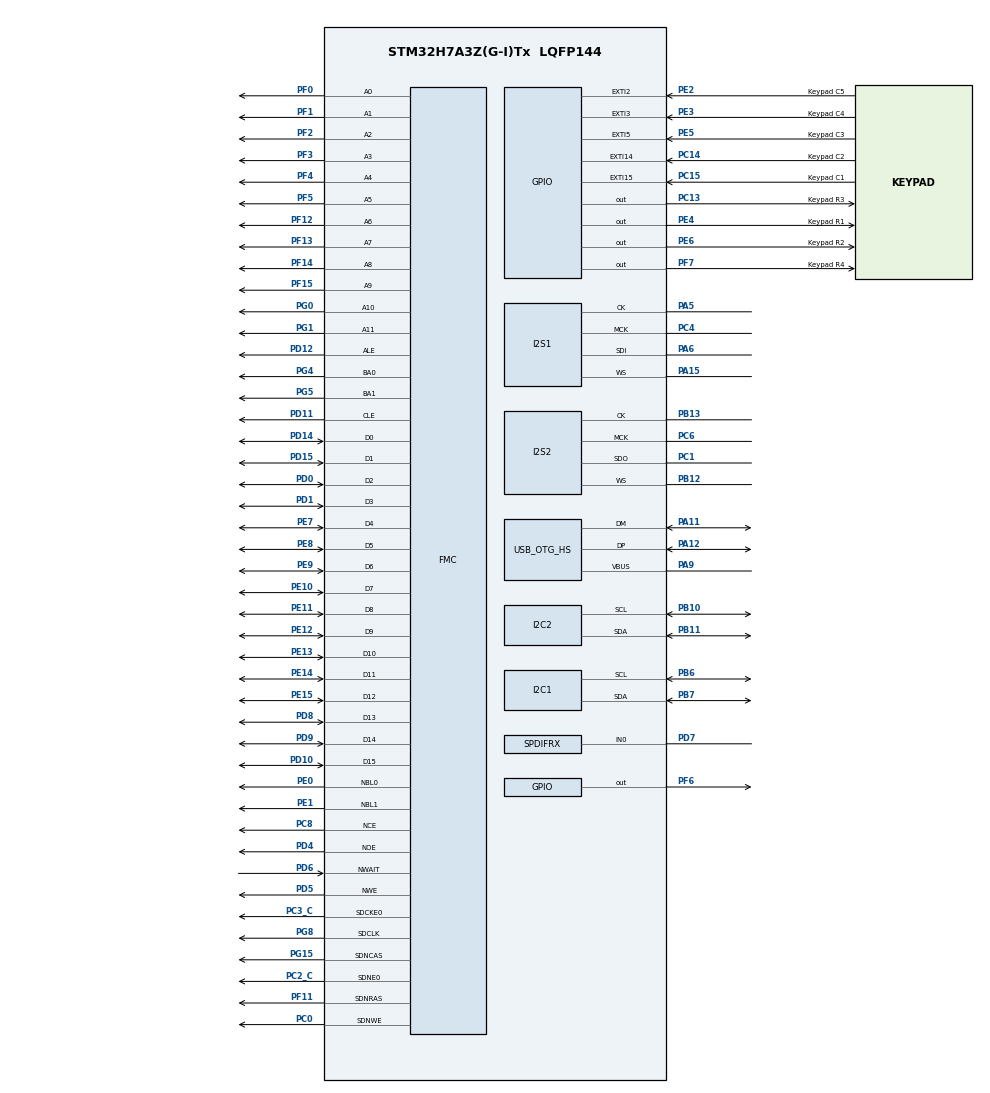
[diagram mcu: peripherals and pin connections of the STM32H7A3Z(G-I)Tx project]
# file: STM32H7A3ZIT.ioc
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CORTEX_M7.AccessPermission_S-Cortex_Memory_Protection_Unit_Region1_Settings_S=MPU_REGION_FULL_ACCESS
CORTEX_M7.AccessPermission_S-Cortex_Memory_Protection_Unit_Region2_Settings_S=MPU_REGION_FULL_ACCESS
CORTEX_M7.BaseAddress_S-Cortex_Memory_Protection_Unit_Region1_Settings_S=0xC0000000
CORTEX_M7.BaseAddress_S-Cortex_Memory_Protection_Unit_Region2_Settings_S=0x80000000
CORTEX_M7.DisableExec_S-Cortex_Memory_Protection_Unit_Region2_Settings_S=MPU_INSTRUCTION_ACCESS_ENABLE
CORTEX_M7.Enable_S-Cortex_Memory_Protection_Unit_Region1_Settings_S=MPU_REGION_ENABLE
CORTEX_M7.Enable_S-Cortex_Memory_Protection_Unit_Region2_Settings_S=MPU_REGION_ENABLE
CORTEX_M7.IsBufferable_S-Cortex_Memory_Protection_Unit_Region1_Settings_S=MPU_ACCESS_NOT_BUFFERABLE
CORTEX_M7.IsBufferable_S-Cortex_Memory_Protection_Unit_Region2_Settings_S=MPU_ACCESS_NOT_BUFFERABLE
CORTEX_M7.IsShareable_S-Cortex_Memory_Protection_Unit_Region1_Settings_S=MPU_ACCESS_SHAREABLE
CORTEX_M7.IsShareable_S-Cortex_Memory_Protection_Unit_Region2_Settings_S=MPU_ACCESS_SHAREABLE
CORTEX_M7.Size_S-Cortex_Memory_Protection_Unit_Region1_Settings_S=MPU_REGION_SIZE_16MB
CORTEX_M7.Size_S-Cortex_Memory_Protection_Unit_Region2_Settings_S=MPU_REGION_SIZE_256MB
CORTEX_M7.TypeExtField_S-Cortex_Memory_Protection_Unit_Region1_Settings_S=MPU_TEX_LEVEL1
CORTEX_M7.TypeExtField_S-Cortex_Memory_Protection_Unit_Region2_Settings_S=MPU_TEX_LEVEL1
CORTEX_M7.default_mode_Activation=1
Dma.Request0=SPI1_RX
Dma.Request1=SPI2_TX
Dma.SPI1_RX.0.Direction=DMA_PERIPH_TO_MEMORY
Dma.SPI1_RX.0.EventEnable=DISABLE
Dma.SPI1_RX.0.FIFOMode=DMA_FIFOMODE_DISABLE
Dma.SPI1_RX.0.Instance=DMA1_Stream0
Dma.SPI1_RX.0.MemDataAlignment=DMA_MDATAALIGN_HALFWORD
Dma.SPI1_RX.0.MemInc=DMA_MINC_ENABLE
Dma.SPI1_RX.0.Mode=DMA_CIRCULAR
Dma.SPI1_RX.0.PeriphDataAlignment=DMA_PDATAALIGN_HALFWORD
Dma.SPI1_RX.0.PeriphInc=DMA_PINC_DISABLE
Dma.SPI1_RX.0.Polarity=HAL_DMAMUX_REQ_GEN_RISING
Dma.SPI1_RX.0.Priority=DMA_PRIORITY_LOW
Dma.SPI1_RX.0.RequestNumber=1
Dma.SPI1_RX.0.SignalID=NONE
Dma.SPI1_RX.0.SyncEnable=DISABLE
Dma.SPI1_RX.0.SyncPolarity=HAL_DMAMUX_SYNC_NO_EVENT
Dma.SPI1_RX.0.SyncRequestNumber=1
Dma.SPI1_RX.0.SyncSignalID=NONE
Dma.SPI2_TX.1.Direction=DMA_MEMORY_TO_PERIPH
Dma.SPI2_TX.1.EventEnable=DISABLE
Dma.SPI2_TX.1.FIFOMode=DMA_FIFOMODE_DISABLE
Dma.SPI2_TX.1.Instance=DMA1_Stream1
Dma.SPI2_TX.1.MemDataAlignment=DMA_MDATAALIGN_HALFWORD
Dma.SPI2_TX.1.MemInc=DMA_MINC_ENABLE
Dma.SPI2_TX.1.Mode=DMA_CIRCULAR
Dma.SPI2_TX.1.PeriphDataAlignment=DMA_PDATAALIGN_HALFWORD
Dma.SPI2_TX.1.PeriphInc=DMA_PINC_DISABLE
Dma.SPI2_TX.1.Polarity=HAL_DMAMUX_REQ_GEN_RISING
Dma.SPI2_TX.1.Priority=DMA_PRIORITY_LOW
Dma.SPI2_TX.1.RequestNumber=1
Dma.SPI2_TX.1.SignalID=NONE
Dma.SPI2_TX.1.SyncEnable=DISABLE
Dma.SPI2_TX.1.SyncPolarity=HAL_DMAMUX_SYNC_NO_EVENT
Dma.SPI2_TX.1.SyncRequestNumber=1
Dma.SPI2_TX.1.SyncSignalID=NONE
FMC.AttributeSpaceHiZSetupTime1=2
FMC.AttributeSpaceHoldSetupTime1=1
FMC.AttributeSpaceSetupTime1=0
FMC.AttributeSpaceWaitSetupTime1=1
FMC.CASLatency1=FMC_SDRAM_CAS_LATENCY_3
FMC.ColumnBitsNumber1=FMC_SDRAM_COLUMN_BITS_NUM_9
FMC.CommonSpaceHiZSetupTime1=5
FMC.CommonSpaceHoldSetupTime1=2
FMC.CommonSpaceSetupTime1=1
FMC.CommonSpaceWaitSetupTime1=2
FMC.EccComputation1=FMC_NAND_ECC_ENABLE
FMC.ExitSelfRefreshDelay1=9
FMC.LoadToActiveDelay1=2
FMC.NandBlockNbr1=2048
FMC.NandBlockSize1=64
FMC.NandExtraCommandEnable1=ENABLE
FMC.NandPageSize1=2112
FMC.NandPlaneNbr1=1
FMC.NandSpareAreaSize1=64
FMC.RCDDelay1=3
FMC.RPDelay1=3
FMC.RPDelay2=3
FMC.ReadBurst1=FMC_SDRAM_RBURST_DISABLE
FMC.RowCycleDelay1=9
FMC.RowCycleDelay2=9
FMC.SDClockPeriod1=FMC_SDRAM_CLOCK_PERIOD_2
FMC.SDClockPeriod2=FMC_SDRAM_CLOCK_PERIOD_2
FMC.SelfRefreshTime1=6
FMC.WriteProtection1=FMC_SDRAM_WRITE_PROTECTION_DISABLE
FMC.WriteRecoveryTime1=3
I2C1.Timing=0x20B0CCFF
I2C2.Timing=0x20B0CCFF
I2S1.AudioFreq=I2S_AUDIOFREQ_8K
I2S1.CPOL=I2S_CPOL_LOW
I2S1.DataFormat=I2S_DATAFORMAT_16B
I2S1.ErrorAudioFreq=0.07 %
I2S1.Instance=SPI$Index
I2S1.MasterKeepIOState=I2S_MASTER_KEEP_IO_STATE_ENABLE
I2S1.RealAudioFreq=8.006 KHz
I2S1.Standard=I2S_STANDARD_PHILIPS
I2S2.AudioFreq=I2S_AUDIOFREQ_8K
I2S2.DataFormat=I2S_DATAFORMAT_16B
I2S2.ErrorAudioFreq=0.07 %
I2S2.FirstBit=I2S_FIRSTBIT_MSB
I2S2.Instance=SPI$Index
I2S2.MasterKeepIOState=I2S_MASTER_KEEP_IO_STATE_ENABLE
I2S2.RealAudioFreq=8.006 KHz
Mcu.Family=STM32H7
Mcu.Name=STM32H7A3Z(G-I)Tx
Mcu.Package=LQFP144
NVIC.DMA1_Stream0_IRQn=true\:4\:0\:true\:false\:true\:false\:true\:true
NVIC.DMA1_Stream1_IRQn=true\:4\:0\:true\:false\:true\:true\:true\:true
NVIC.EXTI15_10_IRQn=true\:3\:0\:true\:true\:true\:4\:true\:true\:true
NVIC.EXTI2_IRQn=true\:3\:0\:true\:true\:true\:1\:true\:true\:true
NVIC.EXTI3_IRQn=true\:3\:0\:true\:true\:true\:2\:true\:true\:true
NVIC.EXTI9_5_IRQn=true\:3\:0\:true\:true\:true\:3\:true\:true\:true
NVIC.OTG_HS_EP1_IN_IRQn=true\:0\:0\:false\:false\:true\:true\:true\:true
NVIC.OTG_HS_EP1_OUT_IRQn=true\:0\:0\:false\:false\:true\:true\:true\:true
NVIC.OTG_HS_IRQn=true\:0\:0\:false\:false\:true\:false\:true\:true
NVIC.PriorityGroup=NVIC_PRIORITYGROUP_4
NVIC.SPDIF_RX_IRQn=true\:0\:0\:false\:false\:true\:true\:true\:true
NVIC.SPI1_IRQn=true\:0\:0\:false\:false\:true\:true\:true\:true
NVIC.SPI2_IRQn=true\:0\:0\:false\:false\:true\:true\:true\:true
NVIC.TIM2_IRQn=true\:0\:0\:false\:false\:true\:true\:true\:true
PA11.GPIO_PuPd=GPIO_NOPULL
PA11.Mode=Device_Only_FS
PA11.Signal=USB_OTG_HS_DM
PA12.GPIO_PuPd=GPIO_PULLUP
PA12.Mode=Device_Only_FS
PA12.Signal=USB_OTG_HS_DP
PA13.Mode=Serial_Wire
PA13.Signal=DEBUG_JTMS-SWDIO
PA14.Mode=Serial_Wire
PA14.Signal=DEBUG_JTCK-SWCLK
PA15.Mode=Half_Duplex_Master_Rx
PA15.Signal=I2S1_WS
PA5.Mode=Half_Duplex_Master_Rx
PA5.Signal=I2S1_CK
PA6.Mode=Half_Duplex_Master_Rx
PA6.Signal=I2S1_SDI
PA9.Mode=Activate_VBUS_FS
PA9.Signal=USB_OTG_HS_VBUS
PB10.Mode=I2C
PB10.Signal=I2C2_SCL
PB11.Mode=I2C
PB11.Signal=I2C2_SDA
PB12.Mode=Half_Duplex_Master_Tx
PB12.Signal=I2S2_WS
PB13.Mode=Half_Duplex_Master_Tx
PB13.Signal=I2S2_CK
PB6.Mode=I2C
PB6.Signal=I2C1_SCL
PB7.Mode=I2C
PB7.Signal=I2C1_SDA
PC0.Signal=FMC_SDNWE
PC1.Mode=Half_Duplex_Master_Tx
PC1.Signal=I2S2_SDO
PC13.GPIO_Label=Keypad R3
PC13.GPIO_ModeDefaultOutputPP=GPIO_MODE_OUTPUT_PP
PC13.GPIO_PuPd=GPIO_NOPULL
PC13.Signal=GPIO_Output
PC14-OSC32_IN.GPIO_Label=Keypad C2
PC14-OSC32_IN.GPIO_ModeDefaultEXTI=GPIO_MODE_IT_FALLING
PC14-OSC32_IN.GPIO_PuPd=GPIO_PULLUP
PC14-OSC32_IN.Signal=GPXTI14
PC15-OSC32_OUT.GPIO_Label=Keypad C1
PC15-OSC32_OUT.GPIO_ModeDefaultEXTI=GPIO_MODE_IT_FALLING
PC15-OSC32_OUT.GPIO_PuPd=GPIO_PULLUP
PC15-OSC32_OUT.Signal=GPXTI15
PC2_C.Mode=SdramChipSelect1_1
PC2_C.Signal=FMC_SDNE0
PC3_C.Mode=SdramChipSelect1_1
PC3_C.Signal=FMC_SDCKE0
PC4.Mode=Master_Clock_Activated
PC4.Signal=I2S1_MCK
PC6.Mode=Master_Clock_Activated
PC6.Signal=I2S2_MCK
PC8.Mode=NandChipSelect3_1
PC8.Signal=FMC_NCE
PD0.Signal=FMC_D2_DA2
PD1.Signal=FMC_D3_DA3
PD10.Signal=FMC_D15_DA15
PD11.Signal=FMC_A16_CLE
PD12.Signal=FMC_A17_ALE
PD14.Signal=FMC_D0_DA0
PD15.Signal=FMC_D1_DA1
PD4.Signal=FMC_NOE
PD5.Signal=FMC_NWE
PD6.Signal=FMC_NWAIT
PD7.Mode=IN0
PD7.Signal=SPDIFRX_IN0
PD8.Signal=FMC_D13_DA13
PD9.Signal=FMC_D14_DA14
PE0.Signal=FMC_NBL0
PE1.Signal=FMC_NBL1
PE10.Signal=FMC_D7_DA7
PE11.Signal=FMC_D8_DA8
PE12.Signal=FMC_D9_DA9
PE13.Signal=FMC_D10_DA10
PE14.Signal=FMC_D11_DA11
PE15.Signal=FMC_D12_DA12
PE2.GPIO_Label=Keypad C5
PE2.GPIO_ModeDefaultEXTI=GPIO_MODE_IT_FALLING
PE2.GPIO_PuPd=GPIO_PULLUP
PE2.Signal=GPXTI2
PE3.GPIO_Label=Keypad C4
PE3.GPIO_ModeDefaultEXTI=GPIO_MODE_IT_FALLING
PE3.GPIO_PuPd=GPIO_PULLUP
PE3.Signal=GPXTI3
PE4.GPIO_Label=Keypad R1
PE4.GPIO_ModeDefaultOutputPP=GPIO_MODE_OUTPUT_PP
PE4.GPIO_PuPd=GPIO_NOPULL
PE4.GPIO_Speed=GPIO_SPEED_FREQ_VERY_HIGH
PE4.Signal=GPIO_Output
PE5.GPIO_Label=Keypad C3
PE5.GPIO_ModeDefaultEXTI=GPIO_MODE_IT_FALLING
PE5.GPIO_PuPd=GPIO_PULLUP
PE5.Signal=GPXTI5
PE6.GPIO_Label=Keypad R2
PE6.GPIO_ModeDefaultOutputPP=GPIO_MODE_OUTPUT_PP
PE6.GPIO_PuPd=GPIO_NOPULL
PE6.GPIO_Speed=GPIO_SPEED_FREQ_VERY_HIGH
PE6.Signal=GPIO_Output
PE7.Signal=FMC_D4_DA4
PE8.Signal=FMC_D5_DA5
PE9.Signal=FMC_D6_DA6
PF0.Signal=FMC_A0
PF1.Signal=FMC_A1
PF11.Signal=FMC_SDNRAS
PF12.Signal=FMC_A6
PF13.Signal=FMC_A7
PF14.Signal=FMC_A8
PF15.Signal=FMC_A9
PF2.Signal=FMC_A2
PF3.Signal=FMC_A3
PF4.Signal=FMC_A4
PF5.Signal=FMC_A5
PF6.Signal=GPIO_Output
PF7.GPIO_Label=Keypad R4
PF7.GPIO_ModeDefaultOutputPP=GPIO_MODE_OUTPUT_PP
PF7.GPIO_PuPd=GPIO_NOPULL
PF7.GPIO_Speed=GPIO_SPEED_FREQ_VERY_HIGH
PF7.Signal=GPIO_Output
PG0.Signal=FMC_A10
PG1.Signal=FMC_A11
PG15.Signal=FMC_SDNCAS
PG4.Signal=FMC_A14_BA0
PG5.Signal=FMC_A15_BA1
PG8.Signal=FMC_SDCLK
ProjectManager.HeapSize=0x200
ProjectManager.StackSize=0x1000
ProjectManager.TargetToolchain=STM32CubeIDE
RCC.ADCFreq_Value=90181818.18181819
RCC.APB1Freq_Value=140000000
RCC.APB2Freq_Value=140000000
RCC.APB3Freq_Value=140000000
RCC.APB4Freq_Value=140000000
RCC.CDPPRE=RCC_APB3_DIV2
RCC.CDPPRE1=RCC_APB1_DIV2
RCC.CDPPRE2=RCC_APB2_DIV2
RCC.CortexFreq_Value=280000000
RCC.DIVM1=4
RCC.DIVM2=33
RCC.DIVN1=35
RCC.DIVN2=279
RCC.DIVP2=6
RCC.FMCCLockSelection=RCC_FMCCLKSOURCE_CLKP
RCC.HCLKFreq_Value=280000000
RCC.PLL2FRACN=0
RCC.PLL3FRACN=0
RCC.PLLFRACN=0
RCC.PLLSourceVirtual=RCC_PLLSOURCE_HSI
RCC.SPI123CLockSelection=RCC_SPI123CLKSOURCE_PLL2
RCC.SRDPPRE=RCC_APB4_DIV2
RCC.SYSCLKFreq_VALUE=280000000
RCC.SYSCLKSource=RCC_SYSCLKSOURCE_PLLCLK
RCC.USBCLockSelection=RCC_USBCLKSOURCE_HSI48
RCC.USBFreq_Value=48000000
SH.FMC_A0.0=FMC_A0,12b-sda1
SH.FMC_A1.0=FMC_A1,12b-sda1
SH.FMC_A10.0=FMC_A10,12b-sda1
SH.FMC_A11.0=FMC_A11,12b-sda1
SH.FMC_A14_BA0.0=FMC_BA0,FourSdramBanks1
SH.FMC_A15_BA1.0=FMC_BA1,FourSdramBanks1
SH.FMC_A16_CLE.0=FMC_CLE,8b-dmux1
SH.FMC_A17_ALE.0=FMC_ALE,8b-dmux1
SH.FMC_A2.0=FMC_A2,12b-sda1
SH.FMC_A3.0=FMC_A3,12b-sda1
SH.FMC_A4.0=FMC_A4,12b-sda1
SH.FMC_A5.0=FMC_A5,12b-sda1
SH.FMC_A6.0=FMC_A6,12b-sda1
SH.FMC_A7.0=FMC_A7,12b-sda1
SH.FMC_A8.0=FMC_A8,12b-sda1
SH.FMC_A9.0=FMC_A9,12b-sda1
SH.FMC_D0_DA0.0=FMC_D0,8b-dmux1
SH.FMC_D0_DA0.1=FMC_D0,sd-16b-d1
SH.FMC_D10_DA10.0=FMC_D10,sd-16b-d1
SH.FMC_D11_DA11.0=FMC_D11,sd-16b-d1
SH.FMC_D12_DA12.0=FMC_D12,sd-16b-d1
SH.FMC_D13_DA13.0=FMC_D13,sd-16b-d1
SH.FMC_D14_DA14.0=FMC_D14,sd-16b-d1
SH.FMC_D15_DA15.0=FMC_D15,sd-16b-d1
SH.FMC_D1_DA1.0=FMC_D1,8b-dmux1
SH.FMC_D1_DA1.1=FMC_D1,sd-16b-d1
SH.FMC_D2_DA2.0=FMC_D2,8b-dmux1
SH.FMC_D2_DA2.1=FMC_D2,sd-16b-d1
SH.FMC_D3_DA3.0=FMC_D3,8b-dmux1
SH.FMC_D3_DA3.1=FMC_D3,sd-16b-d1
SH.FMC_D4_DA4.0=FMC_D4,8b-dmux1
SH.FMC_D4_DA4.1=FMC_D4,sd-16b-d1
SH.FMC_D5_DA5.0=FMC_D5,8b-dmux1
SH.FMC_D5_DA5.1=FMC_D5,sd-16b-d1
SH.FMC_D6_DA6.0=FMC_D6,8b-dmux1
SH.FMC_D6_DA6.1=FMC_D6,sd-16b-d1
SH.FMC_D7_DA7.0=FMC_D7,8b-dmux1
SH.FMC_D7_DA7.1=FMC_D7,sd-16b-d1
SH.FMC_D8_DA8.0=FMC_D8,sd-16b-d1
SH.FMC_D9_DA9.0=FMC_D9,sd-16b-d1
SH.FMC_NBL0.0=FMC_NBL0,Sd2ByteEnable1
SH.FMC_NBL1.0=FMC_NBL1,Sd2ByteEnable1
SH.FMC_NOE.0=FMC_NOE,8b-dmux1
SH.FMC_NWAIT.0=FMC_NWAIT,Wait1
SH.FMC_NWE.0=FMC_NWE,8b-dmux1
SH.FMC_SDCLK.0=FMC_SDCLK,12b-sda1
SH.FMC_SDNCAS.0=FMC_SDNCAS,12b-sda1
SH.FMC_SDNRAS.0=FMC_SDNRAS,12b-sda1
SH.FMC_SDNWE.0=FMC_SDNWE,12b-sda1
SPDIFRX.Retries=SPDIFRX_MAXRETRIES_3
SPDIFRX.StereoMode=SPDIFRX_STEREOMODE_ENABLE
SPDIFRX.SymbolClockGen=DISABLE
SPDIFRX.WaitForActivity=SPDIFRX_WAITFORACTIVITY_OFF
TIM2.Period=6349205
TIM2.Prescaler=0
TIM2.TIM_MasterOutputTrigger=TIM_TRGO_UPDATE
USB_DEVICE.CLASS_NAME_HS=CDC
USB_DEVICE.USBD_DEBUG_LEVEL=3
USB_DEVICE.USBD_SELF_POWERED=1
USB_DEVICE.VirtualMode=Cdc
USB_DEVICE.VirtualModeHS=Cdc_HS
USB_OTG_HS.VirtualMode-Device_Only_FS=Device_Only_FS
VP_MEMORYMAP_VS_MEMORYMAP.Mode=CurAppReg
VP_TIM2_VS_ClockSourceINT.Mode=Internal
VP_USB_DEVICE_VS_USB_DEVICE_CDC_HS.Mode=CDC_HS
board=custom

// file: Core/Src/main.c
/* USER CODE BEGIN Header */
/**
 ******************************************************************************
 * @file           : main.c
 * @brief          : Main program body
 ******************************************************************************
 * @attention
 *
 * Copyright (c) 2024 STMicroelectronics.
 * All rights reserved.
 *
 * This software is licensed under terms that can be found in the LICENSE file
 * in the root directory of this software component.
 * If no LICENSE file comes with this software, it is provided AS-IS.
 *
 ******************************************************************************
 */
/* USER CODE END Header */
#include "main.h"
#include "dma.h"
#include "i2c.h"
#include "i2s.h"
#include "memorymap.h"
#include "spdifrx.h"
#include "tim.h"
#include "usb_device.h"
#include "gpio.h"
#include "fmc.h"

/* USER CODE BEGIN Includes */
#include "usbd_cdc_if.h"
#include "sdram_init.h"

#include "lcdhandler.h"
#include "keypad.h"
#include "stm32h7xx_it.h"
#include "DIX9211init.h"
#include "SineWave.h"
#include "dataCompression.h"
/* USER CODE END Includes */

/* USER CODE BEGIN PM */
#define TEST_END 50
#define TEST_BEGIN (TEST_END - 50)
#define BUFFER_SIZE 64
#define CSIZE1 BUFFER_SIZE/2
#define CSIZE2 CSIZE1/2
#define SPDIF_BUFF_SIZE  4
#define STEP_SIZE	2
#define TX	1
#define RX	0
/* USER CODE END PM */

void SystemClock_Config(void);
void PeriphCommonClock_Config(void);
static void MPU_Config(void);
static void MX_NVIC_Init(void);
/* USER CODE BEGIN PFP */
void testRAM(void);
int testFlash(uint8_t addr, uint8_t data);
void processData(void);
/* USER CODE END PFP */

/* USER CODE BEGIN 0 */
extern NAND_HandleTypeDef hnand1; // for nand flash init
volatile int mode = RX;
volatile int drmode = 0;
extern int switchFlag;
extern const uint16_t sineLookupTable[];
volatile int errFlag = 0;
volatile int RxCplt[12];
volatile int TxCplt[12];
volatile int globalVar = 0;
int memtest = 1;
volatile int clipGo[12];
volatile int clipStore[12];
uint8_t dataReadyFlag=0; //FLAG TO START PROCESSING
volatile uint16_t adc_buf_i2s[BUFFER_SIZE]; //ARRAY FOR AUDIO INPUT
volatile uint16_t dac_buf_i2s[BUFFER_SIZE]; //ARRAY FOR AUDIO OUTPUT [BUFFER_SIZE]
volatile uint16_t channelbuf[CSIZE1]; // CSIZE1
volatile uint16_t depthbuf[CSIZE2]; // CSIZE2

/* USER CODE END 0 */

int main(void)
{

  /* MPU Configuration--------------------------------------------------------*/
  MPU_Config();

  /* MCU Configuration--------------------------------------------------------*/

  /* Reset of all peripherals, Initializes the Flash interface and the Systick. */
  HAL_Init();

  /* Configure the system clock */
  SystemClock_Config();

  /* Configure the peripherals common clocks */
  PeriphCommonClock_Config();

  /* Initialize all configured peripherals */
  MX_GPIO_Init();
  MX_DMA_Init();
  MX_FMC_Init();
  MX_I2S1_Init();
  MX_I2S2_Init();
  MX_SPDIFRX_Init();
  MX_I2C1_Init();
  MX_I2C2_Init();
  MX_USB_DEVICE_Init();
  MX_TIM2_Init();

  /* Initialize interrupts */
  MX_NVIC_Init();
  /* USER CODE BEGIN 2 */
	flashBoot();
	DIX9211init();
	int RxCnt = 0;
	int TxCnt = 0;
	extern SPDIFRX_HandleTypeDef hspdif; // for spdifrx init
	__IO uint32_t spdifrxBuf[SPDIF_BUFF_SIZE] = {0};
	//uint8_t fart[BUFFER_SIZE]
	uint16_t *fart1;
	//testRAM();
  /* USER CODE END 2 */

  /* Infinite loop */
  /* USER CODE BEGIN WHILE */
	//*(__IO uint16_t*) (SDRAM_BANK_ADDR) = 0xAAAA;
	for (int i = 0; i < 12; i++) {
		RxCplt[i] = 0;
		TxCplt[i] = 0;
	}
	HAL_I2S_Receive_DMA(&hi2s1, adc_buf_i2s, BUFFER_SIZE);
	HAL_I2S_Transmit_DMA(&hi2s2, dac_buf_i2s, BUFFER_SIZE);
	testRAM();
	//HAL_I2S_DMAPause(&hi2s2);
	//HAL_I2S_DMAResume(&hi2s2);
	while (1) {

		for(int clip = 0; clip < 12; clip++) {
			if (RxCplt[clip] >= 12000 && drmode != 1) { // 12000 for 45s at 64 buffer size
				RxCplt[clip] = 0;
			}
//(SDRAM_CX_BASE(clip) - 2000000000 + STEP_SIZE*(BUFFER_SIZE/2 + (BUFFER_SIZE/2) * RxCplt[clip])) >= SDRAM_CX_BASE(clip+1) - 2000000000
//SDRAM_CX_BASE(clip)
			//(SDRAM_CX_BASE(clip) + STEP_SIZE*(i/2 + (BUFFER_SIZE/2) * TxCplt[clip]))
			if (TxCplt[clip] >= 12000 && drmode != 1) {
				TxCplt[clip] = 0;
			}
		}
	}

    /* USER CODE END WHILE */

    /* USER CODE BEGIN 3 */

		// The following 4 comments are here for reference and/or copy pasting from

		//HAL_NAND_Write_Page_8b
		//HAL_NAND_Read_Page_8b
		//uint8_t str[] = "Hello World\r\n";
		//CDC_Transmit_HS(str, sizeof(str));

  /* USER CODE END 3 */
}

void SystemClock_Config(void)
{
  RCC_OscInitTypeDef RCC_OscInitStruct = {0};
  RCC_ClkInitTypeDef RCC_ClkInitStruct = {0};

  /*AXI clock gating */
  RCC->CKGAENR = 0xFFFFFFFF;

  /** Supply configuration update enable
  */
  HAL_PWREx_ConfigSupply(PWR_LDO_SUPPLY);

  /** Configure the main internal regulator output voltage
  */
  __HAL_PWR_VOLTAGESCALING_CONFIG(PWR_REGULATOR_VOLTAGE_SCALE0);

  while(!__HAL_PWR_GET_FLAG(PWR_FLAG_VOSRDY)) {}

  /** Initializes the RCC Oscillators according to the specified parameters
  * in the RCC_OscInitTypeDef structure.
  */
  RCC_OscInitStruct.OscillatorType = RCC_OSCILLATORTYPE_HSI48|RCC_OSCILLATORTYPE_HSI;
  RCC_OscInitStruct.HSIState = RCC_HSI_DIV1;
  RCC_OscInitStruct.HSICalibrationValue = 64;
  RCC_OscInitStruct.HSI48State = RCC_HSI48_ON;
  RCC_OscInitStruct.PLL.PLLState = RCC_PLL_ON;
  RCC_OscInitStruct.PLL.PLLSource = RCC_PLLSOURCE_HSI;
  RCC_OscInitStruct.PLL.PLLM = 4;
  RCC_OscInitStruct.PLL.PLLN = 35;
  RCC_OscInitStruct.PLL.PLLP = 2;
  RCC_OscInitStruct.PLL.PLLQ = 2;
  RCC_OscInitStruct.PLL.PLLR = 2;
  RCC_OscInitStruct.PLL.PLLRGE = RCC_PLL1VCIRANGE_3;
  RCC_OscInitStruct.PLL.PLLVCOSEL = RCC_PLL1VCOWIDE;
  RCC_OscInitStruct.PLL.PLLFRACN = 0;
  if (HAL_RCC_OscConfig(&RCC_OscInitStruct) != HAL_OK)
  {
    Error_Handler();
  }

  /** Initializes the CPU, AHB and APB buses clocks
  */
  RCC_ClkInitStruct.ClockType = RCC_CLOCKTYPE_HCLK|RCC_CLOCKTYPE_SYSCLK
                              |RCC_CLOCKTYPE_PCLK1|RCC_CLOCKTYPE_PCLK2
                              |RCC_CLOCKTYPE_D3PCLK1|RCC_CLOCKTYPE_D1PCLK1;
  RCC_ClkInitStruct.SYSCLKSource = RCC_SYSCLKSOURCE_PLLCLK;
  RCC_ClkInitStruct.SYSCLKDivider = RCC_SYSCLK_DIV1;
  RCC_ClkInitStruct.AHBCLKDivider = RCC_HCLK_DIV1;
  RCC_ClkInitStruct.APB3CLKDivider = RCC_APB3_DIV2;
  RCC_ClkInitStruct.APB1CLKDivider = RCC_APB1_DIV2;
  RCC_ClkInitStruct.APB2CLKDivider = RCC_APB2_DIV2;
  RCC_ClkInitStruct.APB4CLKDivider = RCC_APB4_DIV2;

  if (HAL_RCC_ClockConfig(&RCC_ClkInitStruct, FLASH_LATENCY_6) != HAL_OK)
  {
    Error_Handler();
  }
}

void PeriphCommonClock_Config(void)
{
  RCC_PeriphCLKInitTypeDef PeriphClkInitStruct = {0};

  /** Initializes the peripherals clock
  */
  PeriphClkInitStruct.PeriphClockSelection = RCC_PERIPHCLK_SPI2|RCC_PERIPHCLK_SPI1
                              |RCC_PERIPHCLK_CKPER;
  PeriphClkInitStruct.PLL2.PLL2M = 33;
  PeriphClkInitStruct.PLL2.PLL2N = 279;
  PeriphClkInitStruct.PLL2.PLL2P = 6;
  PeriphClkInitStruct.PLL2.PLL2Q = 2;
  PeriphClkInitStruct.PLL2.PLL2R = 2;
  PeriphClkInitStruct.PLL2.PLL2RGE = RCC_PLL2VCIRANGE_0;
  PeriphClkInitStruct.PLL2.PLL2VCOSEL = RCC_PLL2VCOMEDIUM;
  PeriphClkInitStruct.PLL2.PLL2FRACN = 0;
  PeriphClkInitStruct.CkperClockSelection = RCC_CLKPSOURCE_HSI;
  PeriphClkInitStruct.Spi123ClockSelection = RCC_SPI123CLKSOURCE_PLL2;
  if (HAL_RCCEx_PeriphCLKConfig(&PeriphClkInitStruct) != HAL_OK)
  {
    Error_Handler();
  }
}

/**
  * @brief NVIC Configuration.
  * @retval None
  */
static void MX_NVIC_Init(void)
{
  /* EXTI2_IRQn interrupt configuration */
  HAL_NVIC_SetPriority(EXTI2_IRQn, 3, 0);
  HAL_NVIC_EnableIRQ(EXTI2_IRQn);
  /* EXTI3_IRQn interrupt configuration */
  HAL_NVIC_SetPriority(EXTI3_IRQn, 3, 0);
  HAL_NVIC_EnableIRQ(EXTI3_IRQn);
  /* EXTI9_5_IRQn interrupt configuration */
  HAL_NVIC_SetPriority(EXTI9_5_IRQn, 3, 0);
  HAL_NVIC_EnableIRQ(EXTI9_5_IRQn);
  /* EXTI15_10_IRQn interrupt configuration */
  HAL_NVIC_SetPriority(EXTI15_10_IRQn, 3, 0);
  HAL_NVIC_EnableIRQ(EXTI15_10_IRQn);
}

/* USER CODE BEGIN 4 */

void HAL_I2S_RxCpltCallback(I2S_HandleTypeDef *hi2s) {
	if (mode == TX) {
		HAL_I2S_DMAPause(&hi2s1);
		for (int clip = 0; clip < 12; clip++) {
			//RxCplt[clip] = 0;
		}
		HAL_I2S_DMAResume(&hi2s2);
	}
	//channelDeletor(adc_buf_i2s + BUFFER_SIZE/2, channelbuf + CSIZE1/2, BUFFER_SIZE/2);
	for(int i = BUFFER_SIZE/2; i < BUFFER_SIZE; i+=2) {
		for (int clip = 0; clip < 12; clip++) {
			if (clipStore[clip] == 1)
				*(__IO uint16_t*) (SDRAM_CX_BASE(clip) + STEP_SIZE*(i/2 + (BUFFER_SIZE/2) * RxCplt[clip])) = adc_buf_i2s[i];
		}
		//*(__IO uint16_t*) (SDRAM_BANK_ADDR + STEP_SIZE*(i/2 + (BUFFER_SIZE/2) * RxCplt)) = adc_buf_i2s[i];
	}

	//HAL_I2S_Transmit_DMA(&hi2s2, dac_buf_i2s, BUFFER_SIZE);
	//RxCplt++;
	for (int clip = 0; clip < 12; clip++) {
			if (clipStore[clip] == 1) RxCplt[clip]++;
	}
	globalVar++;
}
void HAL_I2S_TxCpltCallback(I2S_HandleTypeDef *hi2s) {
	/* Mode Switching */
	if (mode == RX) {
		HAL_I2S_DMAPause(&hi2s2);
		for (int clip = 0; clip < 12; clip++) {
			//TxCplt[clip] = 0;
		}
		HAL_I2S_DMAResume(&hi2s1);
	}
	/* Data Reading */
	//for (int i = BUFFER_SIZE/2; i < BUFFER_SIZE; i+=2) {
		//dac_buf_i2s[i] = 0;
	//}
	for (int i = BUFFER_SIZE/2; i < BUFFER_SIZE; i+=2) {
		dac_buf_i2s[i] = 0;
		for (int clip = 0; clip < 12; clip++) {
			if (clipGo[clip] == 1)
				dac_buf_i2s[i] += *(__IO uint16_t*) (SDRAM_CX_BASE(clip) + STEP_SIZE*(i/2 + (BUFFER_SIZE/2) * TxCplt[clip]));
		}
		//dac_buf_i2s[i] = *(__IO uint16_t*) (SDRAM_BANK_ADDR + STEP_SIZE*(i/2 + (BUFFER_SIZE/2) * TxCplt));
	}
	//channelRestorer(channelbuf + CSIZE1/2, dac_buf_i2s + BUFFER_SIZE/2, CSIZE1);
	for (int clip = 0; clip < 12; clip++) {
		if (clipGo[clip] == 1) TxCplt[clip]++;
	}

	globalVar++;
}
void HAL_I2S_RxHalfCpltCallback(I2S_HandleTypeDef *hi2s) {
	//RxCplt = 5;
	//channelDeletor(adc_buf_i2s, channelbuf, BUFFER_SIZE/2); // Fills
	for(int i = 0; i < BUFFER_SIZE/2; i+=2) {
		for (int clip = 0; clip < 12; clip++) {
			if (clipStore[clip] == 1)
				*(__IO uint16_t*) (SDRAM_CX_BASE(clip) + STEP_SIZE*(i/2 + (BUFFER_SIZE/2) * RxCplt[clip])) = adc_buf_i2s[i];
		}
		//*(__IO uint16_t*) (SDRAM_BANK_ADDR + STEP_SIZE*(i/2 + (BUFFER_SIZE/2) * RxCplt)) = adc_buf_i2s[i];
	}
}
void HAL_I2S_TxHalfCpltCallback(I2S_HandleTypeDef *hi2s) {
	//TxCplt = 5;
	//for(int i = 0; i < BUFFER_SIZE/2; i+=2) {
	//	dac_buf_i2s[i] = 0;
	//}
	for(int i = 0; i < BUFFER_SIZE/2; i+=2) {
		dac_buf_i2s[i] = 0;
		for (int clip = 0; clip < 12; clip++) {
			if (clipGo[clip] == 1)
				dac_buf_i2s[i] += *(__IO uint16_t*) (SDRAM_CX_BASE(clip) + STEP_SIZE*(i/2 + (BUFFER_SIZE/2) * TxCplt[clip]));
		}
		//dac_buf_i2s[i] = *(__IO uint16_t*) (SDRAM_BANK_ADDR + STEP_SIZE*(i/2 + (BUFFER_SIZE/2) * TxCplt));
	}
	// channelRestorer(channelbuf, dac_buf_i2s, CSIZE1);
}
void HAL_I2S_ErrorCallback(I2S_HandleTypeDef *hi2s) {
	errFlag = 1;
}

void HAL_GPIO_EXTI_Callback(uint16_t GPIO_Pin) {
	int key = GetKey();
	HAL_Delay(200);
	if (key <= 12 && key >= 0) {

		if (mode == TX) clipGo[key] = !clipGo[key]; // Toggle playback
		if (mode == RX)  {
			for (int clip = 0; clip < 12; clip++) { // Clear every storage, only store 1 at a time
				if (clip != key) clipStore[clip] = 0;
			}
			HAL_Delay(10);
			clipStore[key] = !clipStore[key]; // Turn store off and on
		}
	}
	// 15 16 and 17 will be pitch control
	if (key == 15) { // Pitch Down
		HAL_I2S_DMAPause(&hi2s2);
		HAL_I2S_DeInit(&hi2s2);
		hi2s2.Init.AudioFreq = 7200UL;
		HAL_I2S_Init(&hi2s2);
		HAL_I2S_Transmit_DMA(&hi2s2, dac_buf_i2s, BUFFER_SIZE);
	} else if (key == 16) { // Pitch Normal
		HAL_I2S_DMAPause(&hi2s2);
		HAL_I2S_DeInit(&hi2s2);
		hi2s2.Init.AudioFreq = 8000UL;
		HAL_I2S_Init(&hi2s2);
		HAL_I2S_Transmit_DMA(&hi2s2, dac_buf_i2s, BUFFER_SIZE);
	} else if (key == 17) { // Pitch Up
		HAL_I2S_DMAPause(&hi2s2);
		HAL_I2S_DeInit(&hi2s2);
		hi2s2.Init.AudioFreq = 8800UL;
		HAL_I2S_Init(&hi2s2);
		HAL_I2S_Transmit_DMA(&hi2s2, dac_buf_i2s, BUFFER_SIZE);
	} else if (key == 18) { // drmode
		HAL_I2S_DMAPause(&hi2s2);
		HAL_I2S_DMAPause(&hi2s1);
		HAL_I2S_DeInit(&hi2s2);
		HAL_I2S_DeInit(&hi2s1);
		hi2s2.Init.AudioFreq = 44100UL;
		hi2s1.Init.AudioFreq = 44100UL;
		HAL_I2S_Init(&hi2s2);
		HAL_I2S_Init(&hi2s1);
		HAL_I2S_Transmit_DMA(&hi2s2, dac_buf_i2s, BUFFER_SIZE);
		HAL_I2S_Receive_DMA(&hi2s1, adc_buf_i2s, BUFFER_SIZE);
		drmode = !drmode;
	} else if (key == 13) { // Reset Current Clip
		  for (int clip = 0; clip < 12; clip++) {
			  if((clipGo[clip] == 1) || (clipStore[clip] == 1)) {
				  RxCplt[clip] = 0;
				  TxCplt[clip] = 0;
			  }
		  }
	} else if (key == 14) { // Reset All Clips
		for (int clip = 0; clip < 12; clip++) {
			RxCplt[clip] = 0;
			TxCplt[clip] = 0;
		}
	}
	/*switch (key) { // Assumes key cant be changed anywhere else
		case 0:
			if (mode == TX) clipGo[key] = !clipGo[key];
			if (mode == RX) clipStore[key] = !clipStore[key];
			else
			break;
		case 1:
			clipGo[key] = !clipGo[key];
			break;
		case 2:
			clipGo[key] = !clipGo[key];
			break;
		case 3:
			clipGo[key] = !clipGo[key];
			break;
		case 4:
			clipGo[key] = !clipGo[key];
			break;
		case 5:
			clipGo[key] = !clipGo[key];
			break;
		case 6:
			clipGo[key] = !clipGo[key];
			break;
		case 7:
			clipGo[key] = !clipGo[key];
			break;
		case 8:
			clipGo[key] = !clipGo[key];
			break;
		case 9:
			clipGo[key] = !clipGo[key];
			break;
		case 10:
			clipGo[key] = !clipGo[key];
			break;
		case 11:
			clipGo[key] = !clipGo[key];
			break;
		case 12:
			clipGo[key] = !clipGo[key];
			break;
		case 13:
			break;
		case 14:
			break;
		case 15:
			break;
		case 16:
			break;
		case 17:
			break;
		case 18:
			break;
		case 19:
			break;
		default:
			break;
	} */
	if (key == 19) {
		HAL_Delay(10);
		for (int i = 0; i < 12; i++) {
			clipGo[i] = 0;
			clipStore[i] = 0;
		}
		mode = !mode;
	}

}

int testFlash(uint8_t addr, uint8_t data) {
	int ret = 1;
	//NAND_AddressTypeDef Address;
	//Address.Page = 0;
	//Address.Plane = 1;
	//Address.Block = 5;
	//HAL_NAND_Read_Page();
	*(uint8_t*) (FLASH_COMMON_BANK_ADDR + FLASH_ADDRESS_OFFSET) = addr;
	*(uint8_t*) (FLASH_COMMON_BANK_ADDR + FLASH_DATA_OFFSET) = data;
	ret = *(uint8_t*) (FLASH_COMMON_BANK_ADDR + FLASH_DATA_OFFSET);
	return ret;
}

void testRAM(void) {

	volatile uint16_t buffer[TEST_END - TEST_BEGIN];
	for (volatile int i = TEST_BEGIN; i < TEST_END; i++) {
		*(__IO uint16_t*) (SDRAM_BANK_ADDR + 4 * i) = 0x0000; // write to a bunch of memory in the ram
	}
	for (volatile int i = TEST_BEGIN; i < TEST_END; i++) {
		buffer[i - TEST_BEGIN] = *(__IO uint16_t*) (SDRAM_BANK_ADDR + 4 * i); // read from the same memory
		if (buffer[i - TEST_BEGIN] == 0x0000) { // check if its good data

		} else {
			memtest = 0;
		}
	}

	if (memtest) { //printfs
		uint8_t testr[] = "Total RAM Success\r\n";
		CDC_Transmit_HS(testr, sizeof(testr));
	} else {
		uint8_t testr[] = "Partial RAM Failure\r\n";
		CDC_Transmit_HS(testr, sizeof(testr));
	}

}

/* USER CODE END 4 */

 /* MPU Configuration */

void MPU_Config(void)
{
  MPU_Region_InitTypeDef MPU_InitStruct = {0};

  /* Disables the MPU */
  HAL_MPU_Disable();

  /** Initializes and configures the Region and the memory to be protected
  */
  MPU_InitStruct.Enable = MPU_REGION_ENABLE;
  MPU_InitStruct.Number = MPU_REGION_NUMBER0;
  MPU_InitStruct.BaseAddress = 0x0;
  MPU_InitStruct.Size = MPU_REGION_SIZE_4GB;
  MPU_InitStruct.SubRegionDisable = 0x87;
  MPU_InitStruct.TypeExtField = MPU_TEX_LEVEL0;
  MPU_InitStruct.AccessPermission = MPU_REGION_NO_ACCESS;
  MPU_InitStruct.DisableExec = MPU_INSTRUCTION_ACCESS_DISABLE;
  MPU_InitStruct.IsShareable = MPU_ACCESS_SHAREABLE;
  MPU_InitStruct.IsCacheable = MPU_ACCESS_NOT_CACHEABLE;
  MPU_InitStruct.IsBufferable = MPU_ACCESS_NOT_BUFFERABLE;

  HAL_MPU_ConfigRegion(&MPU_InitStruct);

  /** Initializes and configures the Region and the memory to be protected
  */
  MPU_InitStruct.Number = MPU_REGION_NUMBER1;
  MPU_InitStruct.BaseAddress = 0xC0000000;
  MPU_InitStruct.Size = MPU_REGION_SIZE_16MB;
  MPU_InitStruct.SubRegionDisable = 0x0;
  MPU_InitStruct.TypeExtField = MPU_TEX_LEVEL1;
  MPU_InitStruct.AccessPermission = MPU_REGION_FULL_ACCESS;
  MPU_InitStruct.DisableExec = MPU_INSTRUCTION_ACCESS_ENABLE;

  HAL_MPU_ConfigRegion(&MPU_InitStruct);

  /** Initializes and configures the Region and the memory to be protected
  */
  MPU_InitStruct.Number = MPU_REGION_NUMBER2;
  MPU_InitStruct.BaseAddress = 0x80000000;
  MPU_InitStruct.Size = MPU_REGION_SIZE_256MB;

  HAL_MPU_ConfigRegion(&MPU_InitStruct);
  /* Enables the MPU */
  HAL_MPU_Enable(MPU_PRIVILEGED_DEFAULT);

}

void Error_Handler(void)
{
	__disable_irq();
	while (1) {
	}
}
